# YC3122 register map
Series: ARMCM0; File version: 1.0
ARM 32-bit Cortex-M0 Microcontroller based device, CPU clock up to 80MHz, etc.
CPU: CM0 r1p0, little endian, no MPU, no FPU, 8 interrupt priority bits
Registers are 32-bit, read-write, reset 0x0 unless marked. A register's access mark holds for its fields unless they carry their own. Offsets are from the block's base; lines under a group give offsets from that group; [hi:lo] are bit positions; {n}, {i} and the like mark numbered series; 'fields as' and 'values as' point back to an identical list; <NAME> marks a mode.

## Memory map
0x000D0000 MMCU size 0x110
0x000D8080 MMPU size 0x80
0x000D8400 MHSPI size 0x34
0x000F0000 MWDT size 0x10
0x000F0400 MSCI0 size 0x90
0x000F0800 MSCI1 size 0x90
0x000F0C00 MTIM size 0x78 — 32 TIMER
0x000F8204 MCRC size 0x7E
0x000F8400 MRCC size 0x2C
0x000F8520 MSYSCTRL size 0x48
0x000F8574 MRSTGEN size 0xC
0x000F85C0 MSECURE size 0x1C
0x000F8700 MGPIO size 0xE1 — 8 GPIO
0x000F8800 MDMA size 0x1C — 32 DMA
0x000F8800 MDMA_QSPI size 0x1C — QSPI
0x000F8900 MDMA_SPI0 size 0x1C
0x000F891C MSPI size 0x4
0x000F891C MSPI0 size 0x4
0x000F8A00 MDMA_SPI1 size 0x1C
0x000F8A1C MSPI1 size 0x4
0x000F8B00 MDMA_UART0 size 0x1C
0x000F8B1C MUART size 0x10
0x000F8B1C MUART0 size 0x10
0x000F8C00 MDMA_UART1 size 0x1C
0x000F8C1C MUART1 size 0x10
0x000F8D00 MDMA_UART2 size 0x1C
0x000F8D1C MUART2 size 0x10
0x000F8E00 MDMA_UART3 size 0x1C
0x000F8E1C MUART3 size 0x10
0x000F8F00 MDMA_7811 size 0x1C
0x000F8F00 MISO7811 size 0x60
0x000F9000 MDMA_MEMCP size 0x1C
0x000F9100 MDMA_IIC0 size 0x1C
0x000F911C MIIC size 0x8
0x000F911C MI2C0 size 0x8
0x000F9200 MDMA_IIC1 size 0x1C
0x000F921C MI2C1 size 0x8
0x000FA800 MLPM size 0x328
0x000FAC00 MBPK size 0x94
0x000FAE00 MSEC size 0xC8
0x000FAF00 MRTC size 0x18
0x000FAF00 MRTCLSI size 0x18
0x000FB000 MRTCLSE size 0x18
0x000FB200 ANA_LDO_CLK size 0x4 — 32 ANA_LDO_CLK
0x000FB210 ANA_BBPLL size 0x1C — 32 ANA_BBPLL
0x000FB230 ANA_MCR size 0xC — 32 ANA_MCR
0x000FB240 ADC_ANALOG size 0x8 — 32 ADC_ANALOG
0x000FB260 ANA_RNG size 0x8 — 32 ANA_RNG
0x000FB270 ANA_CHGR size 0x4 — 32 ANA
0x000FB400 USB size 0x3A — 32 USB
0x000FBB00 MADC size 0x50

## Interrupts
0 USB (MMCU)
1 I2C0 (MMCU)
2 I2C1 (MMCU)
3 QSPI (MMCU)
4 SPI0 (MMCU)
5 SPI1 (MMCU)
6 HSPI (MMCU)
7 SEC (MMCU)
8 UART0 (MMCU)
9 UART1 (MMCU)
10 UART2 (MMCU)
11 UART3 (MMCU)
12 MEMCP (MMCU)
13 SCI0 (MMCU)
14 SCI1 (MMCU)
15 MSR (MMCU)
16 GPIO (MMCU)
17 TMRG0 (MMCU)
18 TMRG1 (MMCU)
19 SDIO (MMCU)
20 PSARM (MMCU)
21 RSA (MMCU)
22 SM4 (MMCU)
23 TRNG (MMCU)
24 WDT (MMCU)
25 DCMI (MMCU)
26 ADC (MMCU)
27 RTC (MMCU)
28 RSVD1 (MMCU)
29 POWER (MMCU)
30 SOFTWARE (MMCU)
31 RISCV (MMCU)

## MMCU
Base 0x000D0000
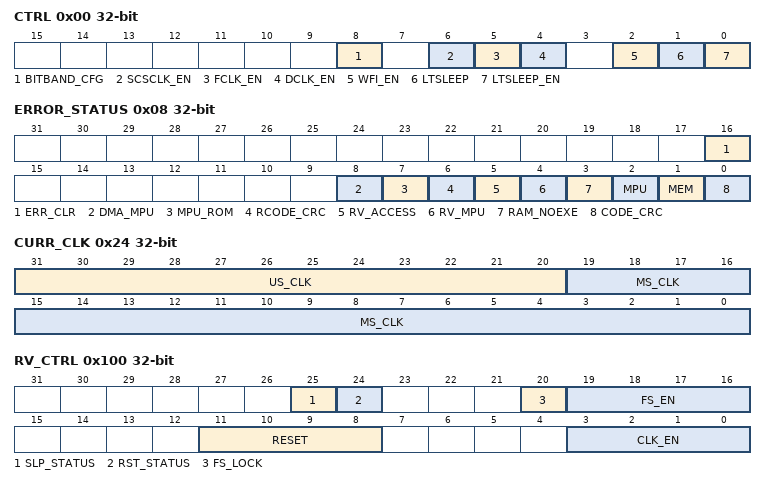
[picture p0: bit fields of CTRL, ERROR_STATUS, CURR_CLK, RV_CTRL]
0x00 CTRL
  [8] BITBAND_CFG — bitband 每一BIT对应的地址长度(0x2. 0000对应的地址是0x800000). 0: RAM每一BIT对应的地址长度是8-bit. 1: RAM每一BIT对应的地址长度是32-bit
  [6] SCSCLK_EN — m0 scsclk的使能
  [5] FCLK_EN — m0 fclk的使能
  [4] DCLK_EN — m0 dclk的使能
  [2] WFI_EN — m0 WFI的使能
  [1] LTSLEEP — 写1 M0,进入浅睡眠模式 注意:此BIT写1后必须要有6个以上的NOP指令,否则退 出浅睡眠时可能会出错
  [0] LTSLEEP_EN wo — 使能 lightsleep
0x04 WKUP_SRC
  [31:0] VAL — 唤醒中断源设置: 每1bit对应0~31号中断
0x08 ERROR_STATUS
  [16] ERR_CLR — 写1会清除所有的CPU ERROR状态
  [8] DMA_MPU ro — 当这1bit置1,代表DMA MPU错误
  [7] MPU_ROM ro — 当这1bit置1,代表rom区域非法访问
  [6] RCODE_CRC ro — 当这1bit置1,代表RV代码读取CRC校验错误
  [5] RV_ACCESS ro — 当这1bit置1,代表risc-v访问不存在的地 址空间
  [4] RV_MPU ro — 当这1bit置1,代表RV MPU错误
  [3] RAM_NOEXE ro — 当这1bit置1,代表M0 RAM执行代码错误
  [2] MPU ro — 当这1bit置1,代表M0 MPU错误
  [1] MEM ro — 当这1bit置1,代表ROM或RAM奇偶校验错误
  [0] CODE_CRC ro — 当这1bit置1,代表M0的代码 CRC校验错误
0x20 IRQ_ADDR0
  [31:0] VAL — M0的中断起始地址
0x24 CURR_CLK
  [31:20] US_CLK — DELAY_US所需时钟(单位CLK)
  [19:0] MS_CLK — DELAY_MS所需时钟(单位CLK)
0x100 RV_CTRL
  [25] SLP_STATUS ro — RV睡眠状态 1:睡眠 0:没有睡眠
  [24] RST_STATUS ro — RV复位状态 1:复位 0:没有复位
  [20] FS_LOCK — RV独立睡眠配置锁定 1: 锁定 FS_LOCK和FS_EN
  [19:16] FS_EN — RV独立睡眠配置 0xa: M0和RV独立睡眠 others: M0睡眠会强制RV一起睡眠
  [11:8] RESET — RV复位使能 0x0a: enable risc-v others: reset riscv
  [3:0] CLK_EN — RV 时钟使能 0x0a: 使能 risc-v clock others: 失能 risc-v clock
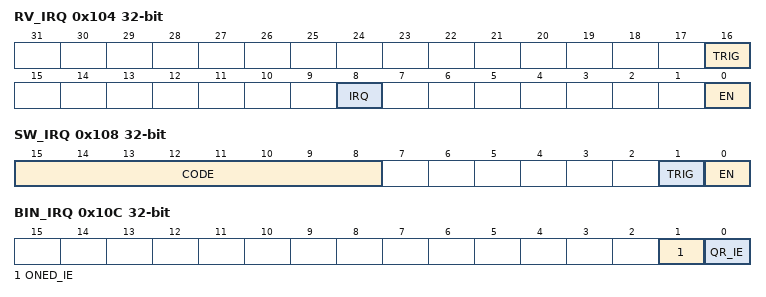
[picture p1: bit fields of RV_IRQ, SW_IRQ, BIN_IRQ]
0x104 RV_IRQ
  [16] TRIG — 写‘1’会触发m0_to_rv中断,中断pend ing寄存器和wakeup enable配置在riscv 寄存器中 必须写0清除,否则会导致一直触发
  [8] IRQ — rv_to_m0中断状态位,使能之前必须先清除一 下该标志位,否则上次中断状态会直接触发中断
  [0] EN — rv_to_m0中断使能
0x108 SW_IRQ
  [15:8] CODE — 用户软件自己可以操作的8BIT
  [1] TRIG — 软件写1会触发软件中断
  [0] EN — M0软件中断使能
0x10C BIN_IRQ
  [1] ONED_IE — 一维码二值化中断使能
  [0] QR_IE — 二维码二值化中断使能

## Licence text in the file
YC is supplying the software is provided for YC3122 microprocessor.
